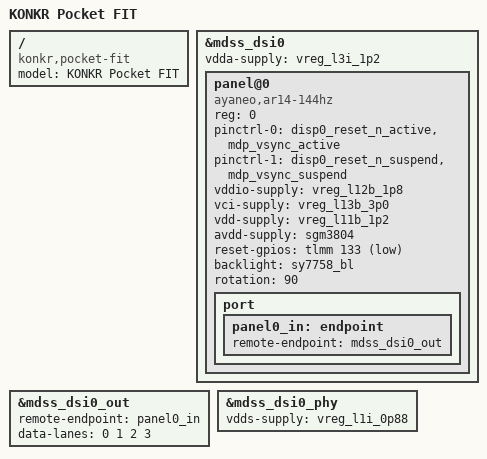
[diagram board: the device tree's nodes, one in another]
// SPDX-License-Identifier: BSD-3-Clause
/*
 * Copyright (c) 2023, Linaro Limited
 * Copyright (c) 2025, Kancy Joe <kancy2333@outlook.com>
 */

/dts-v1/;

#include "sm8650-ayaneo-common.dtsi"

/ {
	model = "KONKR Pocket FIT";
	compatible = "konkr,pocket-fit", "qcom,sm8650";
};

&mdss_dsi0 {
	status = "okay";
	vdda-supply = <&vreg_l3i_1p2>;

	panel@0 {
		status = "okay";
		compatible = "ayaneo,ar14-144hz";
		reg = <0>;
		pinctrl-names = "default", "sleep";
		pinctrl-0 = <&disp0_reset_n_active>, <&mdp_vsync_active>;
		pinctrl-1 = <&disp0_reset_n_suspend>, <&mdp_vsync_suspend>;

		vddio-supply = <&vreg_l12b_1p8>;
		vci-supply = <&vreg_l13b_3p0>;
		vdd-supply = <&vreg_l11b_1p2>;
		avdd-supply = <&sgm3804>;

		reset-gpios = <&tlmm 133 GPIO_ACTIVE_LOW>;
		backlight = <&sy7758_bl>;
		rotation = <90>;

		port {
			panel0_in: endpoint {
				remote-endpoint = <&mdss_dsi0_out>;
			};
		};
	};
};

&mdss_dsi0_out {
	remote-endpoint = <&panel0_in>;
	data-lanes = <0 1 2 3>;
};

&mdss_dsi0_phy {
	vdds-supply = <&vreg_l1i_0p88>;

	status = "okay";
};
